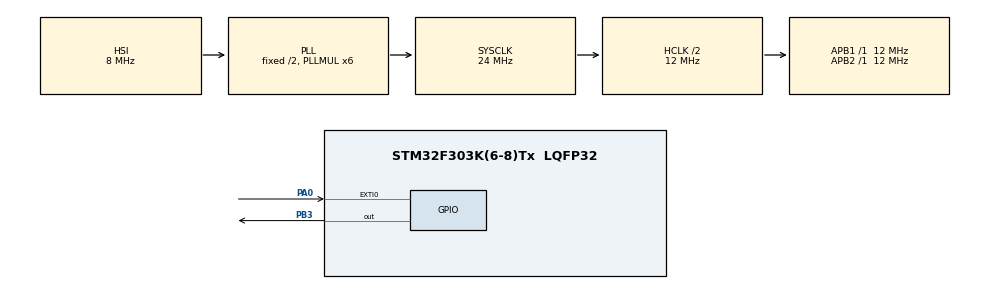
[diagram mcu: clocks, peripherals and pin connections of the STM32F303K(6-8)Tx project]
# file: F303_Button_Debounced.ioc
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Mcu.Family=STM32F3
Mcu.Name=STM32F303K(6-8)Tx
Mcu.Package=LQFP32
NVIC.EXTI0_IRQn=true\:0\:0\:false\:false\:true\:true\:true
NVIC.PriorityGroup=NVIC_PRIORITYGROUP_4
NVIC.TIM2_IRQn=true\:0\:0\:false\:false\:true\:true\:true
PA0.GPIO_PuPd=GPIO_PULLUP
PA0.Signal=GPXTI0
PA13.Mode=Serial_Wire
PA13.Signal=SYS_JTMS-SWDIO
PA14.Mode=Serial_Wire
PA14.Signal=SYS_JTCK-SWCLK
PB3.Signal=GPIO_Output
PF0\ /\ OSC_IN.Mode=HSE-External-Oscillator
PF0\ /\ OSC_IN.Signal=RCC_OSC_IN
PF1\ /\ OSC_OUT.Mode=HSE-External-Oscillator
PF1\ /\ OSC_OUT.Signal=RCC_OSC_OUT
ProjectManager.HeapSize=0x200
ProjectManager.StackSize=0x400
ProjectManager.TargetToolchain=STM32CubeIDE
RCC.AHBCLKDivider=RCC_SYSCLK_DIV2
RCC.AHBFreq_Value=12000000
RCC.APB1Freq_Value=12000000
RCC.APB1TimFreq_Value=12000000
RCC.APB2Freq_Value=12000000
RCC.APB2TimFreq_Value=12000000
RCC.CortexFreq_Value=12000000
RCC.HCLKFreq_Value=12000000
RCC.HSE_VALUE=8000000
RCC.HSI_VALUE=8000000
RCC.PLLMUL=RCC_PLL_MUL6
RCC.SYSCLKFreq_VALUE=24000000
RCC.SYSCLKSourceVirtual=RCC_SYSCLKSOURCE_PLLCLK
TIM2.Period=120
TIM2.Prescaler=11999
VP_TIM2_VS_ClockSourceINT.Mode=Internal
board=custom

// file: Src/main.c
/* USER CODE BEGIN Header */
/**
  ******************************************************************************
  * @file           : main.c
  * @brief          : Main program body
  ******************************************************************************
  * @attention
  *
  * <h2><center>&copy; Copyright (c) 2019 STMicroelectronics.
  * All rights reserved.</center></h2>
  *
  * This software component is licensed by ST under BSD 3-Clause license,
  * the "License"; You may not use this file except in compliance with the
  * License. You may obtain a copy of the License at:
  *                        opensource.org/licenses/BSD-3-Clause
  *
  ******************************************************************************
  */
/* USER CODE END Header */

#include "main.h"

TIM_HandleTypeDef htim2;

void SystemClock_Config(void);
static void MX_GPIO_Init(void);
static void MX_TIM2_Init(void);

int main(void)
{

  /* MCU Configuration--------------------------------------------------------*/

  /* Reset of all peripherals, Initializes the Flash interface and the Systick. */
  HAL_Init();

  /* Configure the system clock */
  SystemClock_Config();

  /* Initialize all configured peripherals */
  MX_GPIO_Init();
  MX_TIM2_Init();

  /* Infinite loop */
  while (1)
  {

  }
}

void SystemClock_Config(void)
{
  RCC_OscInitTypeDef RCC_OscInitStruct = {0};
  RCC_ClkInitTypeDef RCC_ClkInitStruct = {0};

  /** Initializes the CPU, AHB and APB busses clocks
  */
  RCC_OscInitStruct.OscillatorType = RCC_OSCILLATORTYPE_HSI;
  RCC_OscInitStruct.HSIState = RCC_HSI_ON;
  RCC_OscInitStruct.HSICalibrationValue = RCC_HSICALIBRATION_DEFAULT;
  RCC_OscInitStruct.PLL.PLLState = RCC_PLL_ON;
  RCC_OscInitStruct.PLL.PLLSource = RCC_PLLSOURCE_HSI;
  RCC_OscInitStruct.PLL.PLLMUL = RCC_PLL_MUL6;
  if (HAL_RCC_OscConfig(&RCC_OscInitStruct) != HAL_OK)
  {
    Error_Handler();
  }
  /** Initializes the CPU, AHB and APB busses clocks
  */
  RCC_ClkInitStruct.ClockType = RCC_CLOCKTYPE_HCLK|RCC_CLOCKTYPE_SYSCLK
                              |RCC_CLOCKTYPE_PCLK1|RCC_CLOCKTYPE_PCLK2;
  RCC_ClkInitStruct.SYSCLKSource = RCC_SYSCLKSOURCE_PLLCLK;
  RCC_ClkInitStruct.AHBCLKDivider = RCC_SYSCLK_DIV2;
  RCC_ClkInitStruct.APB1CLKDivider = RCC_HCLK_DIV1;
  RCC_ClkInitStruct.APB2CLKDivider = RCC_HCLK_DIV1;

  if (HAL_RCC_ClockConfig(&RCC_ClkInitStruct, FLASH_LATENCY_0) != HAL_OK)
  {
    Error_Handler();
  }
}

static void MX_TIM2_Init(void)
{

  TIM_ClockConfigTypeDef sClockSourceConfig = {0};
  TIM_MasterConfigTypeDef sMasterConfig = {0};

  htim2.Instance = TIM2;
  htim2.Init.Prescaler = 11999;
  htim2.Init.CounterMode = TIM_COUNTERMODE_UP;
  htim2.Init.Period = 120;
  htim2.Init.ClockDivision = TIM_CLOCKDIVISION_DIV1;
  htim2.Init.AutoReloadPreload = TIM_AUTORELOAD_PRELOAD_DISABLE;
  if (HAL_TIM_Base_Init(&htim2) != HAL_OK)
  {
    Error_Handler();
  }
  sClockSourceConfig.ClockSource = TIM_CLOCKSOURCE_INTERNAL;
  if (HAL_TIM_ConfigClockSource(&htim2, &sClockSourceConfig) != HAL_OK)
  {
    Error_Handler();
  }
  sMasterConfig.MasterOutputTrigger = TIM_TRGO_RESET;
  sMasterConfig.MasterSlaveMode = TIM_MASTERSLAVEMODE_DISABLE;
  if (HAL_TIMEx_MasterConfigSynchronization(&htim2, &sMasterConfig) != HAL_OK)
  {
    Error_Handler();
  }

}

static void MX_GPIO_Init(void)
{
  GPIO_InitTypeDef GPIO_InitStruct = {0};

  /* GPIO Ports Clock Enable */
  __HAL_RCC_GPIOF_CLK_ENABLE();
  __HAL_RCC_GPIOA_CLK_ENABLE();
  __HAL_RCC_GPIOB_CLK_ENABLE();

  /*Configure GPIO pin Output Level */
  HAL_GPIO_WritePin(GPIOB, GPIO_PIN_3, GPIO_PIN_RESET);

  /*Configure GPIO pin : PA0 */
  GPIO_InitStruct.Pin = GPIO_PIN_0;
  GPIO_InitStruct.Mode = GPIO_MODE_IT_RISING;
  GPIO_InitStruct.Pull = GPIO_PULLUP;
  HAL_GPIO_Init(GPIOA, &GPIO_InitStruct);

  /*Configure GPIO pin : PB3 */
  GPIO_InitStruct.Pin = GPIO_PIN_3;
  GPIO_InitStruct.Mode = GPIO_MODE_OUTPUT_PP;
  GPIO_InitStruct.Pull = GPIO_NOPULL;
  GPIO_InitStruct.Speed = GPIO_SPEED_FREQ_LOW;
  HAL_GPIO_Init(GPIOB, &GPIO_InitStruct);

  /* EXTI interrupt init*/
  HAL_NVIC_SetPriority(EXTI0_IRQn, 0, 0);
  HAL_NVIC_EnableIRQ(EXTI0_IRQn);

}

/* USER CODE BEGIN 4 */
void HAL_GPIO_EXTI_Callback(uint16_t GPIO_Pin) {
	if(GPIO_Pin==GPIO_PIN_0){
		// 120 ms debounce time
		HAL_TIM_Base_Start_IT(&htim2);

		//HAL_TIM_PWM_Start(&htim2, TIM_CHANNEL_1);
	}
}

void HAL_TIM_PeriodElapsedCallback(TIM_HandleTypeDef *htim){
	if (htim == &htim2){
		static uint8_t ready = 0;
		if (ready == 1){
			HAL_GPIO_TogglePin(GPIOB, GPIO_PIN_3);
			HAL_TIM_Base_Stop_IT(&htim2);
		}
		ready = 1;
	}
}
/* USER CODE END 4 */

void Error_Handler(void)
{
}

/************************ (C) COPYRIGHT STMicroelectronics *****END OF FILE****/
